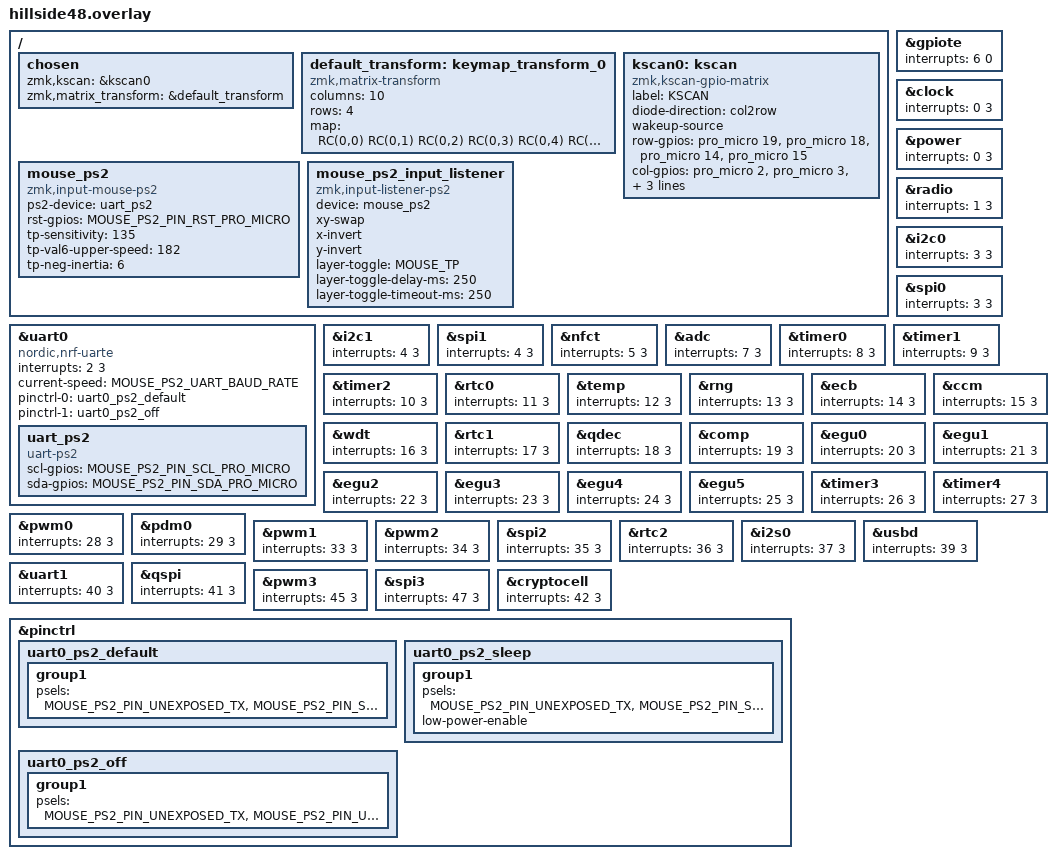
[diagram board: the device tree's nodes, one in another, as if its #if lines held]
/*
 * Copyright (c) 2021 The ZMK Contributors
 *
 * SPDX-License-Identifier: MIT
 */

#include <dt-bindings/zmk/matrix_transform.h>

/ {
    chosen {
        zmk,kscan = &kscan0;
        zmk,matrix_transform = &default_transform;
    };

    default_transform: keymap_transform_0 {
        compatible = "zmk,matrix-transform";
        columns = <10>;
        rows = <4>;

        map = <
RC(0,0) RC(0,1) RC(0,2) RC(0,3) RC(0,4) RC(0,5) RC(0,6) RC(0,7) RC(0,8) RC(0,9) 
RC(1,0) RC(1,1) RC(1,2) RC(1,3) RC(1,4) RC(1,5) RC(1,6) RC(1,7) RC(1,8) RC(1,9)
RC(2,0) RC(2,1) RC(2,2) RC(2,3)         RC(2,5) RC(2,6) RC(2,7) RC(2,8) 
                                RC(3,4) RC(3,5) RC(3,6) 
        >;
    };

    kscan0: kscan {
        compatible = "zmk,kscan-gpio-matrix";
        label = "KSCAN";
        diode-direction = "col2row";
        wakeup-source;

        row-gpios
            = <&pro_micro 19 (GPIO_ACTIVE_HIGH | GPIO_PULL_DOWN)>
			, <&pro_micro 18 (GPIO_ACTIVE_HIGH | GPIO_PULL_DOWN)>
			, <&pro_micro 14 (GPIO_ACTIVE_HIGH | GPIO_PULL_DOWN)>
			, <&pro_micro 15 (GPIO_ACTIVE_HIGH | GPIO_PULL_DOWN)>
			;


        col-gpios
          = <&pro_micro 2 GPIO_ACTIVE_HIGH>
          , <&pro_micro 3 GPIO_ACTIVE_HIGH>
          , <&pro_micro 4 GPIO_ACTIVE_HIGH>
          , <&pro_micro 5 GPIO_ACTIVE_HIGH>
          , <&pro_micro 6 GPIO_ACTIVE_HIGH>
          , <&pro_micro 7 GPIO_ACTIVE_HIGH>
          , <&pro_micro 8 GPIO_ACTIVE_HIGH>
          , <&pro_micro 9 GPIO_ACTIVE_HIGH>
          , <&pro_micro 16 GPIO_ACTIVE_HIGH>
          , <&pro_micro 10 GPIO_ACTIVE_HIGH>
		;
        
    };

};

// #define HAS_MOUSE_TP

#define MOUSE_PS2_DRIVER_UART

#define MOUSE_PS2_PIN_SCL_PRO_MICRO <&pro_micro 1 GPIO_ACTIVE_HIGH>
#define MOUSE_PS2_PIN_SDA_PRO_MICRO <&pro_micro 0 GPIO_ACTIVE_HIGH>

// #define MOUSE_PS2_PIN_RST_PRO_MICRO <&pro_micro 9 GPIO_ACTIVE_HIGH>

#define MOUSE_PS2_PIN_SDA_PINCTRL <NRF_PSEL(UART_RX, 0, 8)>

#define MOUSE_PS2_UART_BAUD_RATE <14400>


/*
 * PS/2 Mouse / Trackpoint - User Configuration if NOT using nice!nano
 *
 * WARNING: Do NOT change this if you are using a nice!nano v2 or clone.
 */

// Unexposed UART pins
#define MOUSE_PS2_PIN_UNEXPOSED_TX <NRF_PSEL(UART_TX, 0, 27)>
#define MOUSE_PS2_PIN_UNEXPOSED_RX <NRF_PSEL(UART_RX, 0, 28)>


// Adjust GPIO interrupt priority to the highest level.
// - CONFIG_BT_CTLR_LLL_PRIO 1
// - CONFIG_BT_CTLR_ULL_HIGH_PRIO 2
// - CONFIG_BT_CTLR_ULL_LOW_PRIOCONFIG 2

// gpiote should have the highest interrupt priority (0)
&gpiote {
    interrupts = < 6 0 >;
};

// All other priorities should be two levels lower than their defaults
// (which is usually 1 and should be demoted to 3)
&clock {
    interrupts = < 0 3 >;
};

&power {
    interrupts = < 0 3 >;
};

&radio {
    interrupts = < 1 3 >;
};

&uart0 {
    interrupts = < 2 3 >;
};

&i2c0 {
    interrupts = < 3 3 >;
};

&spi0 {
    interrupts = < 3 3 >;
};

&i2c1 {
    interrupts = < 4 3 >;
};

&spi1 {
    interrupts = < 4 3 >;
};

&nfct {
    interrupts = < 5 3 >;
};

&adc {
    interrupts = < 7 3 >;
};

&timer0 {
    interrupts = < 8 3 >;
};

&timer1 {
    interrupts = < 9 3 >;
};

&timer2 {
    interrupts = < 10 3 >;
};

&rtc0 {
    interrupts = < 11 3 >;
};

&temp {
    interrupts = < 12 3 >;
};

&rng {
    interrupts = < 13 3 >;
};

&ecb {
    interrupts = < 14 3 >;
};

&ccm {
    interrupts = < 15 3 >;
};

&wdt {
    interrupts = < 16 3 >;
};

&rtc1 {
    interrupts = < 17 3 >;
};

&qdec {
    interrupts = < 18 3 >;
};

&comp {
    interrupts = < 19 3 >;
};

&egu0 {
    interrupts = < 20 3 >;
};

&egu1 {
    interrupts = < 21 3 >;
};

&egu2 {
    interrupts = < 22 3 >;
};

&egu3 {
    interrupts = < 23 3 >;
};

&egu4 {
    interrupts = < 24 3 >;
};

&egu5 {
    interrupts = < 25 3 >;
};

&timer3 {
    interrupts = < 26 3 >;
};

&timer4 {
    interrupts = < 27 3 >;
};

&pwm0 {
    interrupts = < 28 3 >;
};

&pdm0 {
    interrupts = < 29 3 >;
};

&pwm1 {
    interrupts = < 33 3 >;
};

&pwm2 {
    interrupts = < 34 3 >;
};

&spi2 {
    interrupts = < 35 3 >;
};

&rtc2 {
    interrupts = < 36 3 >;
};

&i2s0 {
    interrupts = < 37 3 >;
};

&usbd {
    interrupts = < 39 3 >;
};

&uart1 {
    interrupts = < 40 3 >;
};

&qspi {
    interrupts = < 41 3 >;
};

&pwm3 {
    interrupts = < 45 3 >;
};

&spi3 {
    interrupts = < 47 3 >;
};

&cryptocell {
    interrupts = < 42 3 >;
};


/*
 * PS/2 Mouse / Trackpoint - Device Definitions
 *
 * WARNING: Do not change anything beyond here unless you know what you are
 *          doing.
 */


#define MOUSE_PS2_DT_PRESENT

&pinctrl {
	// This pinctrl state is used for receiving
	// For `UART_TX`, set an unused and unexposed pin
	// For `UART_RX`, set the PS/2 SDA pin number
	uart0_ps2_default: uart0_ps2_default {
		group1 {
			psels = MOUSE_PS2_PIN_UNEXPOSED_TX,
					MOUSE_PS2_PIN_SDA_PINCTRL;
		};
	};

	// Set this to the same pins as uart0_ps2_default
	uart0_ps2_sleep: uart0_ps2_sleep {
		group1 {
			psels = MOUSE_PS2_PIN_UNEXPOSED_TX,
					MOUSE_PS2_PIN_SDA_PINCTRL;
			low-power-enable;
		};
	};

	
	uart0_ps2_off: uart0_ps2_off {
		group1 {
			psels = MOUSE_PS2_PIN_UNEXPOSED_TX,
					MOUSE_PS2_PIN_UNEXPOSED_RX;
		};
	};
};


#ifdef MOUSE_PS2_DRIVER_UART

    &uart0 {
        status = "disabled";
        compatible = "nordic,nrf-uarte";

        current-speed = MOUSE_PS2_UART_BAUD_RATE;
        pinctrl-0 = <&uart0_ps2_default>;
        pinctrl-1 = <&uart0_ps2_off>;

        pinctrl-names = "default", "sleep";

        uart_ps2: uart_ps2 {
            status="disabled";
            compatible = "uart-ps2";
            scl-gpios = MOUSE_PS2_PIN_SCL_PRO_MICRO;
            sda-gpios = MOUSE_PS2_PIN_SDA_PRO_MICRO;
        };
    };

#else

    / {
        gpio_ps2: gpio_ps2 {
            status = "disabled";

            compatible = "gpio-ps2";
            scl-gpios = MOUSE_PS2_PIN_SCL_PRO_MICRO;
            sda-gpios = MOUSE_PS2_PIN_SDA_PRO_MICRO;
        };
    };

#endif


/ {
    mouse_ps2: mouse_ps2 {
		status = "disabled";
        compatible = "zmk,input-mouse-ps2";

#ifdef MOUSE_PS2_DRIVER_UART
	    ps2-device = <&uart_ps2>;
#else
	    ps2-device = <&gpio_ps2>;
#endif

#ifdef MOUSE_PS2_PIN_RST_PRO_MICRO
        rst-gpios = MOUSE_PS2_PIN_RST_PRO_MICRO;
#endif
    };

    mouse_ps2_input_listener: mouse_ps2_input_listener {
        compatible = "zmk,input-listener-ps2";
        status = "disabled";

        device = <&mouse_ps2>;

    };
};


#ifdef HAS_MOUSE_TP
  #include <dt-bindings/zmk/mouse.h>
  #include <dt-bindings/zmk/mouse_settings.h>
  #include <behaviors/mouse_keys.dtsi>
  #include <behaviors/mouse_setting.dtsi>

  // How sensitive the trackpoint is
  #define U_MSS_TP_S_I &mms MS_TP_SENSITIVITY_INCR
  #define U_MSS_TP_S_D &mms MS_TP_SENSITIVITY_DECR


  // The maximum speed the trackpoint will accelerate to
  #define U_MSS_TP_V6_I &mms MS_TP_VALUE6_INCR
  #define U_MSS_TP_V6_D &mms MS_TP_VALUE6_DECR


  // I am not quite sure tbh... default seems fine.
  #define U_MSS_TP_NI_I &mms MS_TP_NEG_INERTIA_INCR
  #define U_MSS_TP_NI_D &mms MS_TP_NEG_INERTIA_DECR


  // How hard you have to press to activate the "Press To Select" feature that
  // lets you tap or press on the trackpoint to click.
  //
  // Not all trackpoints support it and you have to enable
  // `tp-press-to-select;` in `&mouse_ps2` first.
  // #define U_MSS_TP_PT_I &mms MS_TP_PTS_THRESHOLD_INCR
  // #define U_MSS_TP_PT_D &mms MS_TP_PTS_THRESHOLD_DECR


  // If you mess up the settings, you can use this key code to clear the
  // settings from flash and re-set the default values on the TP.
  //
  // Make sure to wait at least CONFIG_ZMK_SETTINGS_SAVE_DEBOUNCE seconds (60
  // by default) before restarting the board to ensure the settings are
  // written to flash storage.
  #define U_MSS_RESET   &mms MS_RESET


  // If you prefer to set the settings in `&mouse_ps2`, you can use the key
  // codes above to find the settings you like the most and then press this
  // key code to output the settings to the log.
  //
  // Then you can add those values to `&mouse_ps2`
  #define U_MSS_LOG     &mms MS_LOG


  // Only apply these settings on the side that has the TP connected
  // (usually the right side)
  #ifdef MOUSE_PS2_DT_PRESENT

   /*
    * Input Listener Config
    */

    &mouse_ps2_input_listener {
      xy-swap;
      x-invert;
      y-invert;

      // Set the layer that should automatically activate when the mouse is
      // moving.
      layer-toggle = <MOUSE_TP>;

      // How long the mouse needs to move for before the layer is activated (to
      // avoid accidental activations while typing) (Default: 250)
      layer-toggle-delay-ms = <250>;

      // How long to wait, after the last mouse movement, before deactivating
      // the layer (Default: 250)
      layer-toggle-timeout-ms = <250>;
    };


   /*
    * Mouse Driver Settings
    */

    &mouse_ps2 {

      // How sensitive the TP is (Default: 128)
      tp-sensitivity = <135>;


      // The maximum mouse movement speed the TP will accelarate to
      // (Default: 97)
      tp-val6-upper-speed = <182>;


      // Not quite sure what it does tbh :) (Default: 6)
      tp-neg-inertia = <6>;


      // Enable clicking by tapping on the TP.
      // Not all TPs support this.
      // tp-press-to-select;
      // tp-press-to-select-threshold = <10>;


      // Adjust axis settings on the TP
      // Works only on some trackpoints, but may be properly considered by the
      // trackpoint's acceleration features (which may or may not have an
      // impact).
      //
      // Alternatively consider achieving the same effect using the
      //  `input-listener` settings below.
      // tp-xy-swap;
      // tp-x-invert;
      // tp-y-invert;


      // Set sampling rate
      //
      // The frequency at which the mouse samples and sends data (in hz).
      // The default rate is 100. You can try lowering it if you experience
      // connection errors.
      //
      // Higher values than 100 are no improvement in my experience, but will
      // increase battery life and potentially errors in transmissions.
      //
      // These values are allowed: 10,20,40,60,80,100,200
      // sampling-rate = <60>;


      // Disables clicking.
      // Useful when using the PS2 GPIO driver that is prone to
      // erros in transmissions to reduce accidental clicks.
      // disable-clicking;


      // Enable scroll wheel
      // For mouse devices supporting the Intellimouse extension. Not relevant
      // for trackpoints
      // scroll-mode;

    };

    // Enable PS/2 Mouse Devices
    // In `your_keyboard_right.overlay` all devices have `status = "disabled"`.
    // So,they are never compiled into the firmware.
    //
    // Here we enable them, but we do it within the #ifdef HAS_MOUSE_TP code
    // block, which allows to prevent compilation and potential build errors
    // when we undefine HAS_MOUSE_TP in corne_tp.keymap
    &mouse_ps2  {
      status = "okay";
    };

    &mouse_ps2_input_listener {
      status = "okay";
    };

    #ifdef MOUSE_PS2_DRIVER_UART

      &uart0 {
        status = "okay";
      };

      &uart_ps2 {
        status="okay";
      };

    #else

      &gpio_ps2  {
        status = "okay";
      };

    #endif  // MOUSE_PS2_DRIVER_UART
  #endif  // MOUSE_PS2_DT_PRESENT
#endif  // HAS_MOUSE_TP
